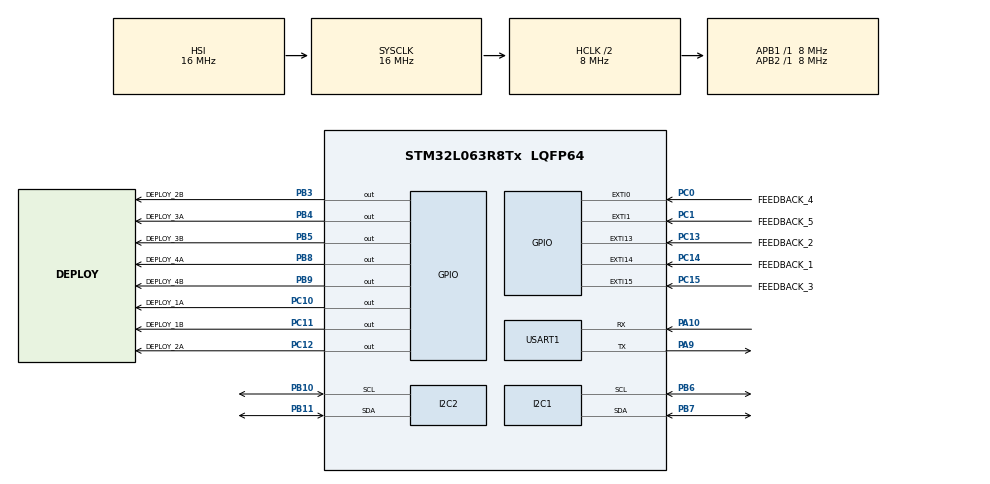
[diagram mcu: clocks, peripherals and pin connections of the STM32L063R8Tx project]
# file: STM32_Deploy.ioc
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ADC.ClockPrescaler=ADC_CLOCK_ASYNC_DIV64
ADC.ContinuousConvMode=DISABLE
ADC.DMAContinuousRequests=DISABLE
ADC.DataAlign=ADC_DATAALIGN_RIGHT
ADC.DiscontinuousConvMode=DISABLE
ADC.EOCSelection=ADC_EOC_SINGLE_CONV
ADC.EnableAnalogWatchDog=false
ADC.ExternalTrigConv=ADC_SOFTWARE_START
ADC.ExternalTrigConvEdge=ADC_EXTERNALTRIGCONVEDGE_NONE
ADC.LowPowerAutoPowerOff=DISABLE
ADC.LowPowerAutoWait=DISABLE
ADC.LowPowerFrequencyMode=DISABLE
ADC.Overrun=ADC_OVR_DATA_PRESERVED
ADC.OversamplingMode=DISABLE
ADC.Resolution=ADC_RESOLUTION_12B
ADC.SamplingTime=ADC_SAMPLETIME_12CYCLES_5
ADC.ScanConvMode=ADC_SCAN_DIRECTION_FORWARD
Dma.ADC.4.Direction=DMA_PERIPH_TO_MEMORY
Dma.ADC.4.Instance=DMA1_Channel1
Dma.ADC.4.MemDataAlignment=DMA_MDATAALIGN_HALFWORD
Dma.ADC.4.MemInc=DMA_MINC_ENABLE
Dma.ADC.4.Mode=DMA_NORMAL
Dma.ADC.4.PeriphDataAlignment=DMA_PDATAALIGN_HALFWORD
Dma.ADC.4.PeriphInc=DMA_PINC_DISABLE
Dma.ADC.4.Priority=DMA_PRIORITY_LOW
Dma.I2C1_RX.5.Direction=DMA_PERIPH_TO_MEMORY
Dma.I2C1_RX.5.Instance=DMA1_Channel7
Dma.I2C1_RX.5.MemDataAlignment=DMA_MDATAALIGN_BYTE
Dma.I2C1_RX.5.MemInc=DMA_MINC_ENABLE
Dma.I2C1_RX.5.Mode=DMA_NORMAL
Dma.I2C1_RX.5.PeriphDataAlignment=DMA_PDATAALIGN_BYTE
Dma.I2C1_RX.5.PeriphInc=DMA_PINC_DISABLE
Dma.I2C1_RX.5.Priority=DMA_PRIORITY_LOW
Dma.I2C1_TX.6.Direction=DMA_MEMORY_TO_PERIPH
Dma.I2C1_TX.6.Instance=DMA1_Channel6
Dma.I2C1_TX.6.MemDataAlignment=DMA_MDATAALIGN_BYTE
Dma.I2C1_TX.6.MemInc=DMA_MINC_ENABLE
Dma.I2C1_TX.6.Mode=DMA_NORMAL
Dma.I2C1_TX.6.PeriphDataAlignment=DMA_PDATAALIGN_BYTE
Dma.I2C1_TX.6.PeriphInc=DMA_PINC_DISABLE
Dma.I2C1_TX.6.Priority=DMA_PRIORITY_LOW
Dma.I2C2_RX.2.Direction=DMA_PERIPH_TO_MEMORY
Dma.I2C2_RX.2.Instance=DMA1_Channel5
Dma.I2C2_RX.2.MemDataAlignment=DMA_MDATAALIGN_BYTE
Dma.I2C2_RX.2.MemInc=DMA_MINC_ENABLE
Dma.I2C2_RX.2.Mode=DMA_NORMAL
Dma.I2C2_RX.2.PeriphDataAlignment=DMA_PDATAALIGN_BYTE
Dma.I2C2_RX.2.PeriphInc=DMA_PINC_DISABLE
Dma.I2C2_RX.2.Priority=DMA_PRIORITY_LOW
Dma.I2C2_TX.3.Direction=DMA_MEMORY_TO_PERIPH
Dma.I2C2_TX.3.Instance=DMA1_Channel4
Dma.I2C2_TX.3.MemDataAlignment=DMA_MDATAALIGN_BYTE
Dma.I2C2_TX.3.MemInc=DMA_MINC_ENABLE
Dma.I2C2_TX.3.Mode=DMA_NORMAL
Dma.I2C2_TX.3.PeriphDataAlignment=DMA_PDATAALIGN_BYTE
Dma.I2C2_TX.3.PeriphInc=DMA_PINC_DISABLE
Dma.I2C2_TX.3.Priority=DMA_PRIORITY_LOW
Dma.Request0=USART1_RX
Dma.Request1=USART1_TX
Dma.Request2=I2C2_RX
Dma.Request3=I2C2_TX
Dma.Request4=ADC
Dma.Request5=I2C1_RX
Dma.Request6=I2C1_TX
Dma.USART1_RX.0.Direction=DMA_PERIPH_TO_MEMORY
Dma.USART1_RX.0.Instance=DMA1_Channel3
Dma.USART1_RX.0.MemDataAlignment=DMA_MDATAALIGN_BYTE
Dma.USART1_RX.0.MemInc=DMA_MINC_ENABLE
Dma.USART1_RX.0.Mode=DMA_CIRCULAR
Dma.USART1_RX.0.PeriphDataAlignment=DMA_PDATAALIGN_BYTE
Dma.USART1_RX.0.PeriphInc=DMA_PINC_DISABLE
Dma.USART1_RX.0.Priority=DMA_PRIORITY_LOW
Dma.USART1_TX.1.Direction=DMA_MEMORY_TO_PERIPH
Dma.USART1_TX.1.Instance=DMA1_Channel2
Dma.USART1_TX.1.MemDataAlignment=DMA_MDATAALIGN_BYTE
Dma.USART1_TX.1.MemInc=DMA_MINC_ENABLE
Dma.USART1_TX.1.Mode=DMA_NORMAL
Dma.USART1_TX.1.PeriphDataAlignment=DMA_PDATAALIGN_BYTE
Dma.USART1_TX.1.PeriphInc=DMA_PINC_DISABLE
Dma.USART1_TX.1.Priority=DMA_PRIORITY_LOW
FREERTOS.MEMORY_ALLOCATION=1
FREERTOS.Tasks01=i2cTask,2,128,i2cWork,Default,NULL,Static,i2cTaskBuffer,i2cControlBlock;controlTask,0,64,controlWork,Default,NULL,Static,controlTaskBuffer,controlControlBlock
FREERTOS.configMINIMAL_STACK_SIZE=64
FREERTOS.configUSE_TICKLESS_IDLE=1
I2C1.OwnAddress=16
I2C1.Timing=0x2000090E
I2C2.Timing=0x2000090E
Mcu.Family=STM32L0
Mcu.Name=STM32L063R8Tx
Mcu.Package=LQFP64
NVIC.DMA1_Channel1_IRQn=true\:3\:0\:false\:false\:true\:true
NVIC.DMA1_Channel2_3_IRQn=true\:3\:0\:false\:false\:true\:true
NVIC.DMA1_Channel4_5_6_7_IRQn=true\:3\:0\:false\:false\:true\:true
NVIC.EXTI0_1_IRQn=true\:3\:0\:false\:false\:true\:true
NVIC.EXTI4_15_IRQn=true\:3\:0\:false\:false\:true\:true
NVIC.I2C1_IRQn=true\:3\:0\:false\:false\:true\:true
NVIC.I2C2_IRQn=true\:3\:0\:false\:false\:true\:true
NVIC.TIM2_IRQn=true\:3\:0\:false\:false\:true\:true
NVIC.TIM6_DAC_IRQn=true\:0\:0\:false\:false\:true\:false
NVIC.TimeBase=TIM6_DAC_IRQn
NVIC.TimeBaseIP=TIM6
PA10.Mode=Asynchronous
PA10.Signal=USART1_RX
PA9.Mode=Asynchronous
PA9.Signal=USART1_TX
PB10.Mode=I2C
PB10.Signal=I2C2_SCL
PB11.Mode=I2C
PB11.Signal=I2C2_SDA
PB3.GPIO_Label=DEPLOY_2B
PB3.Signal=GPIO_Output
PB4.GPIO_Label=DEPLOY_3A
PB4.Signal=GPIO_Output
PB5.GPIO_Label=DEPLOY_3B
PB5.Signal=GPIO_Output
PB6.Mode=I2C
PB6.Signal=I2C1_SCL
PB7.Mode=I2C
PB7.Signal=I2C1_SDA
PB8.GPIO_Label=DEPLOY_4A
PB8.Signal=GPIO_Output
PB9.GPIO_Label=DEPLOY_4B
PB9.Signal=GPIO_Output
PC0.GPIO_Label=FEEDBACK_4
PC0.GPIO_ModeDefaultEXTI=GPIO_MODE_IT_RISING
PC0.Signal=GPXTI0
PC1.GPIO_Label=FEEDBACK_5
PC1.Signal=GPXTI1
PC10.GPIO_Label=DEPLOY_1A
PC10.Signal=GPIO_Output
PC11.GPIO_Label=DEPLOY_1B
PC11.Signal=GPIO_Output
PC12.GPIO_Label=DEPLOY_2A
PC12.Signal=GPIO_Output
PC13.GPIO_Label=FEEDBACK_2
PC13.Signal=GPXTI13
PC14-OSC32_IN.GPIO_Label=FEEDBACK_1
PC14-OSC32_IN.Signal=GPXTI14
PC15-OSC32_OUT.GPIO_Label=FEEDBACK_3
PC15-OSC32_OUT.Signal=GPXTI15
ProjectManager.HeapSize=0x200
ProjectManager.StackSize=0x400
ProjectManager.TargetToolchain=SW4STM32
RCC.AHBCLKDivider=RCC_SYSCLK_DIV2
RCC.AHBFreq_Value=8000000
RCC.APB1Freq_Value=8000000
RCC.APB1TimFreq_Value=8000000
RCC.APB2Freq_Value=8000000
RCC.APB2TimFreq_Value=8000000
RCC.HCLKFreq_Value=8000000
RCC.HSE_VALUE=8000000
RCC.HSI16_VALUE=16000000
RCC.HSI48_VALUE=48000000
RCC.HSI_VALUE=16000000
RCC.LSE_VALUE=32768
RCC.MSI_VALUE=2097000
RCC.SYSCLKFreq_VALUE=16000000
RCC.SYSCLKSource=RCC_SYSCLKSOURCE_HSI
RCC.VCOOutputFreq_Value=48000000
TIM2.Period=1000
TIM2.Prescaler=8000
TIM2.TIM_MasterOutputTrigger=TIM_TRGO_RESET
USART1.OverSampling=UART_OVERSAMPLING_16
USART1.VirtualMode-Asynchronous=VM_ASYNC
USART1.WordLength=WORDLENGTH_8B
VP_ADC_TempSens_Input.Mode=IN-TempSens
VP_ADC_Vref_Input.Mode=IN-Vrefint
VP_FREERTOS_VS_ENABLE.Mode=Enabled
VP_SYS_VS_tim6.Mode=TIM6
VP_TIM2_VS_ClockSourceINT.Mode=Internal
VP_TIM2_VS_ClockSourceITR.Mode=TriggerSource_ITR0
VP_TIM2_VS_ControllerModeReset.Mode=Reset Mode
board=STM32_Deploy

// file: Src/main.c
/**
  ******************************************************************************
  * File Name          : main.c
  * Description        : Main program body
  ******************************************************************************
  * This notice applies to any and all portions of this file
  * that are not between comment pairs USER CODE BEGIN and
  * USER CODE END. Other portions of this file, whether
  * inserted by the user or by software development tools
  * are owned by their respective copyright owners.
  *
  * Copyright (c) 2017 STMicroelectronics International N.V.
  * All rights reserved.
  *
  * Redistribution and use in source and binary forms, with or without
  * modification, are permitted, provided that the following conditions are met:
  *
  * 1. Redistribution of source code must retain the above copyright notice,
  *    this list of conditions and the following disclaimer.
  * 2. Redistributions in binary form must reproduce the above copyright notice,
  *    this list of conditions and the following disclaimer in the documentation
  *    and/or other materials provided with the distribution.
  * 3. Neither the name of STMicroelectronics nor the names of other
  *    contributors to this software may be used to endorse or promote products
  *    derived from this software without specific written permission.
  * 4. This software, including modifications and/or derivative works of this
  *    software, must execute solely and exclusively on microcontroller or
  *    microprocessor devices manufactured by or for STMicroelectronics.
  * 5. Redistribution and use of this software other than as permitted under
  *    this license is void and will automatically terminate your rights under
  *    this license.
  *
  * THIS SOFTWARE IS PROVIDED BY STMICROELECTRONICS AND CONTRIBUTORS "AS IS"
  * AND ANY EXPRESS, IMPLIED OR STATUTORY WARRANTIES, INCLUDING, BUT NOT
  * LIMITED TO, THE IMPLIED WARRANTIES OF MERCHANTABILITY, FITNESS FOR A
  * PARTICULAR PURPOSE AND NON-INFRINGEMENT OF THIRD PARTY INTELLECTUAL PROPERTY
  * RIGHTS ARE DISCLAIMED TO THE FULLEST EXTENT PERMITTED BY LAW. IN NO EVENT
  * SHALL STMICROELECTRONICS OR CONTRIBUTORS BE LIABLE FOR ANY DIRECT, INDIRECT,
  * INCIDENTAL, SPECIAL, EXEMPLARY, OR CONSEQUENTIAL DAMAGES (INCLUDING, BUT NOT
  * LIMITED TO, PROCUREMENT OF SUBSTITUTE GOODS OR SERVICES; LOSS OF USE, DATA,
  * OR PROFITS; OR BUSINESS INTERRUPTION) HOWEVER CAUSED AND ON ANY THEORY OF
  * LIABILITY, WHETHER IN CONTRACT, STRICT LIABILITY, OR TORT (INCLUDING
  * NEGLIGENCE OR OTHERWISE) ARISING IN ANY WAY OUT OF THE USE OF THIS SOFTWARE,
  * EVEN IF ADVISED OF THE POSSIBILITY OF SUCH DAMAGE.
  *
  ******************************************************************************
  */
#include "main.h"
#include "stm32l0xx_hal.h"
#include "cmsis_os.h"

/* USER CODE BEGIN Includes */
#include <string.h>
#include "utils.h"
#include "deploy_execution.h"
/* USER CODE END Includes */

ADC_HandleTypeDef hadc;
DMA_HandleTypeDef hdma_adc;

I2C_HandleTypeDef hi2c1;
I2C_HandleTypeDef hi2c2;
DMA_HandleTypeDef hdma_i2c1_rx;
DMA_HandleTypeDef hdma_i2c1_tx;
DMA_HandleTypeDef hdma_i2c2_rx;
DMA_HandleTypeDef hdma_i2c2_tx;

TIM_HandleTypeDef htim2;

UART_HandleTypeDef huart1;
DMA_HandleTypeDef hdma_usart1_rx;
DMA_HandleTypeDef hdma_usart1_tx;

osThreadId i2cTaskHandle;
uint32_t i2cTaskBuffer[ 128 ];
osStaticThreadDef_t i2cControlBlock;
osThreadId controlTaskHandle;
uint32_t controlTaskBuffer[ 64 ];
osStaticThreadDef_t controlControlBlock;

/* USER CODE BEGIN PV */
/* Private variables ---------------------------------------------------------*/

/* USER CODE END PV */

void SystemClock_Config(void);
static void MX_GPIO_Init(void);
static void MX_DMA_Init(void);
static void MX_I2C2_Init(void);
static void MX_I2C1_Init(void);
static void MX_USART1_UART_Init(void);
static void MX_TIM2_Init(void);
static void MX_ADC_Init(void);
void i2cWork(void const * argument);
void controlWork(void const * argument);

/* USER CODE BEGIN PFP */
/* Private function prototypes -----------------------------------------------*/

/* USER CODE END PFP */

int main(void)
{

  /* MCU Configuration----------------------------------------------------------*/

  /* Reset of all peripherals, Initializes the Flash interface and the Systick. */
  HAL_Init();

  /* Configure the system clock */
  SystemClock_Config();

  /* Initialize all configured peripherals */
  MX_GPIO_Init();
  MX_DMA_Init();
  MX_I2C2_Init();
  MX_I2C1_Init();
  MX_USART1_UART_Init();
  MX_TIM2_Init();
  MX_ADC_Init();

  /* USER CODE BEGIN 2 */
  initialize_temp_sensor();

  /* USER CODE END 2 */

  /* Create the thread(s) */
  /* definition and creation of i2cTask */
  osThreadStaticDef(i2cTask, i2cWork, osPriorityHigh, 0, 128, i2cTaskBuffer, &i2cControlBlock);
  i2cTaskHandle = osThreadCreate(osThread(i2cTask), NULL);

  /* definition and creation of controlTask */
  osThreadStaticDef(controlTask, controlWork, osPriorityNormal, 0, 64, controlTaskBuffer, &controlControlBlock);
  controlTaskHandle = osThreadCreate(osThread(controlTask), NULL);

  /* Start scheduler */
  osKernelStart();

  /* We should never get here as control is now taken by the scheduler */

  /* Infinite loop */
  while (1)
  {

  }

}

/** System Clock Configuration
*/
void SystemClock_Config(void)
{

  RCC_OscInitTypeDef RCC_OscInitStruct;
  RCC_ClkInitTypeDef RCC_ClkInitStruct;
  RCC_PeriphCLKInitTypeDef PeriphClkInit;

    /**Configure the main internal regulator output voltage
    */
  __HAL_PWR_VOLTAGESCALING_CONFIG(PWR_REGULATOR_VOLTAGE_SCALE1);

    /**Initializes the CPU, AHB and APB busses clocks
    */
  RCC_OscInitStruct.OscillatorType = RCC_OSCILLATORTYPE_HSI;
  RCC_OscInitStruct.HSIState = RCC_HSI_ON;
  RCC_OscInitStruct.HSICalibrationValue = 16;
  RCC_OscInitStruct.PLL.PLLState = RCC_PLL_NONE;
  if (HAL_RCC_OscConfig(&RCC_OscInitStruct) != HAL_OK)
  {
    _Error_Handler(__FILE__, __LINE__);
  }

    /**Initializes the CPU, AHB and APB busses clocks
    */
  RCC_ClkInitStruct.ClockType = RCC_CLOCKTYPE_HCLK|RCC_CLOCKTYPE_SYSCLK
                              |RCC_CLOCKTYPE_PCLK1|RCC_CLOCKTYPE_PCLK2;
  RCC_ClkInitStruct.SYSCLKSource = RCC_SYSCLKSOURCE_HSI;
  RCC_ClkInitStruct.AHBCLKDivider = RCC_SYSCLK_DIV2;
  RCC_ClkInitStruct.APB1CLKDivider = RCC_HCLK_DIV1;
  RCC_ClkInitStruct.APB2CLKDivider = RCC_HCLK_DIV1;

  if (HAL_RCC_ClockConfig(&RCC_ClkInitStruct, FLASH_LATENCY_0) != HAL_OK)
  {
    _Error_Handler(__FILE__, __LINE__);
  }

  PeriphClkInit.PeriphClockSelection = RCC_PERIPHCLK_USART1|RCC_PERIPHCLK_I2C1;
  PeriphClkInit.Usart1ClockSelection = RCC_USART1CLKSOURCE_PCLK2;
  PeriphClkInit.I2c1ClockSelection = RCC_I2C1CLKSOURCE_PCLK1;
  if (HAL_RCCEx_PeriphCLKConfig(&PeriphClkInit) != HAL_OK)
  {
    _Error_Handler(__FILE__, __LINE__);
  }

    /**Configure the Systick interrupt time
    */
  HAL_SYSTICK_Config(HAL_RCC_GetHCLKFreq()/1000);

    /**Configure the Systick
    */
  HAL_SYSTICK_CLKSourceConfig(SYSTICK_CLKSOURCE_HCLK);

  /* SysTick_IRQn interrupt configuration */
  HAL_NVIC_SetPriority(SysTick_IRQn, 3, 0);
}

/* ADC init function */
static void MX_ADC_Init(void)
{

  ADC_ChannelConfTypeDef sConfig;

    /**Configure the global features of the ADC (Clock, Resolution, Data Alignment and number of conversion)
    */
  hadc.Instance = ADC1;
  hadc.Init.OversamplingMode = DISABLE;
  hadc.Init.ClockPrescaler = ADC_CLOCK_ASYNC_DIV64;
  hadc.Init.Resolution = ADC_RESOLUTION_12B;
  hadc.Init.SamplingTime = ADC_SAMPLETIME_12CYCLES_5;
  hadc.Init.ScanConvMode = ADC_SCAN_DIRECTION_FORWARD;
  hadc.Init.DataAlign = ADC_DATAALIGN_RIGHT;
  hadc.Init.ContinuousConvMode = DISABLE;
  hadc.Init.DiscontinuousConvMode = DISABLE;
  hadc.Init.ExternalTrigConvEdge = ADC_EXTERNALTRIGCONVEDGE_NONE;
  hadc.Init.ExternalTrigConv = ADC_SOFTWARE_START;
  hadc.Init.DMAContinuousRequests = DISABLE;
  hadc.Init.EOCSelection = ADC_EOC_SINGLE_CONV;
  hadc.Init.Overrun = ADC_OVR_DATA_PRESERVED;
  hadc.Init.LowPowerAutoWait = DISABLE;
  hadc.Init.LowPowerFrequencyMode = DISABLE;
  hadc.Init.LowPowerAutoPowerOff = DISABLE;
  if (HAL_ADC_Init(&hadc) != HAL_OK)
  {
    _Error_Handler(__FILE__, __LINE__);
  }

    /**Configure for the selected ADC regular channel to be converted.
    */
  sConfig.Channel = ADC_CHANNEL_TEMPSENSOR;
  sConfig.Rank = ADC_RANK_CHANNEL_NUMBER;
  if (HAL_ADC_ConfigChannel(&hadc, &sConfig) != HAL_OK)
  {
    _Error_Handler(__FILE__, __LINE__);
  }

    /**Configure for the selected ADC regular channel to be converted.
    */
  sConfig.Channel = ADC_CHANNEL_VREFINT;
  if (HAL_ADC_ConfigChannel(&hadc, &sConfig) != HAL_OK)
  {
    _Error_Handler(__FILE__, __LINE__);
  }

}

/* I2C1 init function */
static void MX_I2C1_Init(void)
{

  hi2c1.Instance = I2C1;
  hi2c1.Init.Timing = 0x2000090E;
  hi2c1.Init.OwnAddress1 = 32;
  hi2c1.Init.AddressingMode = I2C_ADDRESSINGMODE_7BIT;
  hi2c1.Init.DualAddressMode = I2C_DUALADDRESS_DISABLE;
  hi2c1.Init.OwnAddress2 = 0;
  hi2c1.Init.OwnAddress2Masks = I2C_OA2_NOMASK;
  hi2c1.Init.GeneralCallMode = I2C_GENERALCALL_DISABLE;
  hi2c1.Init.NoStretchMode = I2C_NOSTRETCH_DISABLE;
  if (HAL_I2C_Init(&hi2c1) != HAL_OK)
  {
    _Error_Handler(__FILE__, __LINE__);
  }

    /**Configure Analogue filter
    */
  if (HAL_I2CEx_ConfigAnalogFilter(&hi2c1, I2C_ANALOGFILTER_ENABLE) != HAL_OK)
  {
    _Error_Handler(__FILE__, __LINE__);
  }

    /**Configure Digital filter
    */
  if (HAL_I2CEx_ConfigDigitalFilter(&hi2c1, 0) != HAL_OK)
  {
    _Error_Handler(__FILE__, __LINE__);
  }

}

/* I2C2 init function */
static void MX_I2C2_Init(void)
{

  hi2c2.Instance = I2C2;
  hi2c2.Init.Timing = 0x2000090E;
  hi2c2.Init.OwnAddress1 = 0;
  hi2c2.Init.AddressingMode = I2C_ADDRESSINGMODE_7BIT;
  hi2c2.Init.DualAddressMode = I2C_DUALADDRESS_DISABLE;
  hi2c2.Init.OwnAddress2 = 0;
  hi2c2.Init.OwnAddress2Masks = I2C_OA2_NOMASK;
  hi2c2.Init.GeneralCallMode = I2C_GENERALCALL_DISABLE;
  hi2c2.Init.NoStretchMode = I2C_NOSTRETCH_DISABLE;
  if (HAL_I2C_Init(&hi2c2) != HAL_OK)
  {
    _Error_Handler(__FILE__, __LINE__);
  }

    /**Configure Analogue filter
    */
  if (HAL_I2CEx_ConfigAnalogFilter(&hi2c2, I2C_ANALOGFILTER_ENABLE) != HAL_OK)
  {
    _Error_Handler(__FILE__, __LINE__);
  }

    /**Configure Digital filter
    */
  if (HAL_I2CEx_ConfigDigitalFilter(&hi2c2, 0) != HAL_OK)
  {
    _Error_Handler(__FILE__, __LINE__);
  }

}

/* TIM2 init function */
static void MX_TIM2_Init(void)
{

  TIM_ClockConfigTypeDef sClockSourceConfig;
  TIM_SlaveConfigTypeDef sSlaveConfig;
  TIM_MasterConfigTypeDef sMasterConfig;

  htim2.Instance = TIM2;
  htim2.Init.Prescaler = 8000;
  htim2.Init.CounterMode = TIM_COUNTERMODE_UP;
  htim2.Init.Period = 1000;
  htim2.Init.ClockDivision = TIM_CLOCKDIVISION_DIV1;
  if (HAL_TIM_Base_Init(&htim2) != HAL_OK)
  {
    _Error_Handler(__FILE__, __LINE__);
  }

  sClockSourceConfig.ClockSource = TIM_CLOCKSOURCE_INTERNAL;
  if (HAL_TIM_ConfigClockSource(&htim2, &sClockSourceConfig) != HAL_OK)
  {
    _Error_Handler(__FILE__, __LINE__);
  }

  sSlaveConfig.SlaveMode = TIM_SLAVEMODE_RESET;
  sSlaveConfig.InputTrigger = TIM_TS_ITR0;
  if (HAL_TIM_SlaveConfigSynchronization(&htim2, &sSlaveConfig) != HAL_OK)
  {
    _Error_Handler(__FILE__, __LINE__);
  }

  sMasterConfig.MasterOutputTrigger = TIM_TRGO_RESET;
  sMasterConfig.MasterSlaveMode = TIM_MASTERSLAVEMODE_DISABLE;
  if (HAL_TIMEx_MasterConfigSynchronization(&htim2, &sMasterConfig) != HAL_OK)
  {
    _Error_Handler(__FILE__, __LINE__);
  }

}

/* USART1 init function */
static void MX_USART1_UART_Init(void)
{

  huart1.Instance = USART1;
  huart1.Init.BaudRate = 115200;
  huart1.Init.WordLength = UART_WORDLENGTH_8B;
  huart1.Init.StopBits = UART_STOPBITS_1;
  huart1.Init.Parity = UART_PARITY_NONE;
  huart1.Init.Mode = UART_MODE_TX_RX;
  huart1.Init.HwFlowCtl = UART_HWCONTROL_NONE;
  huart1.Init.OverSampling = UART_OVERSAMPLING_16;
  huart1.Init.OneBitSampling = UART_ONE_BIT_SAMPLE_DISABLE;
  huart1.AdvancedInit.AdvFeatureInit = UART_ADVFEATURE_NO_INIT;
  if (HAL_UART_Init(&huart1) != HAL_OK)
  {
    _Error_Handler(__FILE__, __LINE__);
  }

}

static void MX_DMA_Init(void)
{
  /* DMA controller clock enable */
  __HAL_RCC_DMA1_CLK_ENABLE();

  /* DMA interrupt init */
  /* DMA1_Channel1_IRQn interrupt configuration */
  HAL_NVIC_SetPriority(DMA1_Channel1_IRQn, 3, 0);
  HAL_NVIC_EnableIRQ(DMA1_Channel1_IRQn);
  /* DMA1_Channel2_3_IRQn interrupt configuration */
  HAL_NVIC_SetPriority(DMA1_Channel2_3_IRQn, 3, 0);
  HAL_NVIC_EnableIRQ(DMA1_Channel2_3_IRQn);
  /* DMA1_Channel4_5_6_7_IRQn interrupt configuration */
  HAL_NVIC_SetPriority(DMA1_Channel4_5_6_7_IRQn, 3, 0);
  HAL_NVIC_EnableIRQ(DMA1_Channel4_5_6_7_IRQn);

}

/** Configure pins as
        * Analog
        * Input
        * Output
        * EVENT_OUT
        * EXTI
*/
static void MX_GPIO_Init(void)
{

  GPIO_InitTypeDef GPIO_InitStruct;

  /* GPIO Ports Clock Enable */
  __HAL_RCC_GPIOC_CLK_ENABLE();
  __HAL_RCC_GPIOB_CLK_ENABLE();
  __HAL_RCC_GPIOA_CLK_ENABLE();

  /*Configure GPIO pin Output Level */
  HAL_GPIO_WritePin(GPIOC, DEPLOY_1A_Pin|DEPLOY_1B_Pin|DEPLOY_2A_Pin, GPIO_PIN_RESET);

  /*Configure GPIO pin Output Level */
  HAL_GPIO_WritePin(GPIOB, DEPLOY_2B_Pin|DEPLOY_3A_Pin|DEPLOY_3B_Pin|DEPLOY_4A_Pin
                          |DEPLOY_4B_Pin, GPIO_PIN_RESET);

  /*Configure GPIO pins : FEEDBACK_2_Pin FEEDBACK_1_Pin FEEDBACK_3_Pin FEEDBACK_4_Pin
                           FEEDBACK_5_Pin */
  GPIO_InitStruct.Pin = FEEDBACK_2_Pin|FEEDBACK_1_Pin|FEEDBACK_3_Pin|FEEDBACK_4_Pin
                          |FEEDBACK_5_Pin;
  GPIO_InitStruct.Mode = GPIO_MODE_IT_RISING;
  GPIO_InitStruct.Pull = GPIO_NOPULL;
  HAL_GPIO_Init(GPIOC, &GPIO_InitStruct);

  /*Configure GPIO pins : DEPLOY_1A_Pin DEPLOY_1B_Pin DEPLOY_2A_Pin */
  GPIO_InitStruct.Pin = DEPLOY_1A_Pin|DEPLOY_1B_Pin|DEPLOY_2A_Pin;
  GPIO_InitStruct.Mode = GPIO_MODE_OUTPUT_PP;
  GPIO_InitStruct.Pull = GPIO_NOPULL;
  GPIO_InitStruct.Speed = GPIO_SPEED_FREQ_LOW;
  HAL_GPIO_Init(GPIOC, &GPIO_InitStruct);

  /*Configure GPIO pins : DEPLOY_2B_Pin DEPLOY_3A_Pin DEPLOY_3B_Pin DEPLOY_4A_Pin
                           DEPLOY_4B_Pin */
  GPIO_InitStruct.Pin = DEPLOY_2B_Pin|DEPLOY_3A_Pin|DEPLOY_3B_Pin|DEPLOY_4A_Pin
                          |DEPLOY_4B_Pin;
  GPIO_InitStruct.Mode = GPIO_MODE_OUTPUT_PP;
  GPIO_InitStruct.Pull = GPIO_NOPULL;
  GPIO_InitStruct.Speed = GPIO_SPEED_FREQ_LOW;
  HAL_GPIO_Init(GPIOB, &GPIO_InitStruct);

  /* EXTI interrupt init*/
  HAL_NVIC_SetPriority(EXTI0_1_IRQn, 3, 0);
  //HAL_NVIC_EnableIRQ(EXTI0_1_IRQn);

  HAL_NVIC_SetPriority(EXTI4_15_IRQn, 3, 0);
  //HAL_NVIC_EnableIRQ(EXTI4_15_IRQn);

}

/* i2cWork function */
void i2cWork(void const * argument)
{

  /* USER CODE BEGIN 5 */
	deploy_command_t cmd;
  /* Infinite loop */
  for(;;)
  {
	  turn_i2c_rx();
	  if (i2c_slave_message()) {
		  get_i2c_message(&cmd);
		  process_incoming(&cmd);
	  }
  }
  /* USER CODE END 5 */
}

/* controlWork function */
void controlWork(void const * argument)
{
  /* USER CODE BEGIN controlWork */
  /* Infinite loop */
  for(;;)
  {
	  deploy_work();
  }
  /* USER CODE END controlWork */
}

void HAL_TIM_PeriodElapsedCallback(TIM_HandleTypeDef *htim)
{
  if (htim->Instance == TIM6) {
    HAL_IncTick();
  }
}

void _Error_Handler(char * file, int line)
{
  while(1)
  {
  }
}

/************************ (C) COPYRIGHT STMicroelectronics *****END OF FILE****/

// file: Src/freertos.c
/**
  ******************************************************************************
  * File Name          : freertos.c
  * Description        : Code for freertos applications
  ******************************************************************************
  * This notice applies to any and all portions of this file
  * that are not between comment pairs USER CODE BEGIN and
  * USER CODE END. Other portions of this file, whether
  * inserted by the user or by software development tools
  * are owned by their respective copyright owners.
  *
  * Copyright (c) 2017 STMicroelectronics International N.V.
  * All rights reserved.
  *
  * Redistribution and use in source and binary forms, with or without
  * modification, are permitted, provided that the following conditions are met:
  *
  * 1. Redistribution of source code must retain the above copyright notice,
  *    this list of conditions and the following disclaimer.
  * 2. Redistributions in binary form must reproduce the above copyright notice,
  *    this list of conditions and the following disclaimer in the documentation
  *    and/or other materials provided with the distribution.
  * 3. Neither the name of STMicroelectronics nor the names of other
  *    contributors to this software may be used to endorse or promote products
  *    derived from this software without specific written permission.
  * 4. This software, including modifications and/or derivative works of this
  *    software, must execute solely and exclusively on microcontroller or
  *    microprocessor devices manufactured by or for STMicroelectronics.
  * 5. Redistribution and use of this software other than as permitted under
  *    this license is void and will automatically terminate your rights under
  *    this license.
  *
  * THIS SOFTWARE IS PROVIDED BY STMICROELECTRONICS AND CONTRIBUTORS "AS IS"
  * AND ANY EXPRESS, IMPLIED OR STATUTORY WARRANTIES, INCLUDING, BUT NOT
  * LIMITED TO, THE IMPLIED WARRANTIES OF MERCHANTABILITY, FITNESS FOR A
  * PARTICULAR PURPOSE AND NON-INFRINGEMENT OF THIRD PARTY INTELLECTUAL PROPERTY
  * RIGHTS ARE DISCLAIMED TO THE FULLEST EXTENT PERMITTED BY LAW. IN NO EVENT
  * SHALL STMICROELECTRONICS OR CONTRIBUTORS BE LIABLE FOR ANY DIRECT, INDIRECT,
  * INCIDENTAL, SPECIAL, EXEMPLARY, OR CONSEQUENTIAL DAMAGES (INCLUDING, BUT NOT
  * LIMITED TO, PROCUREMENT OF SUBSTITUTE GOODS OR SERVICES; LOSS OF USE, DATA,
  * OR PROFITS; OR BUSINESS INTERRUPTION) HOWEVER CAUSED AND ON ANY THEORY OF
  * LIABILITY, WHETHER IN CONTRACT, STRICT LIABILITY, OR TORT (INCLUDING
  * NEGLIGENCE OR OTHERWISE) ARISING IN ANY WAY OUT OF THE USE OF THIS SOFTWARE,
  * EVEN IF ADVISED OF THE POSSIBILITY OF SUCH DAMAGE.
  *
  ******************************************************************************
  */

#include "FreeRTOS.h"
#include "task.h"

/* Pre/Post sleep processing prototypes */
void PreSleepProcessing(uint32_t *ulExpectedIdleTime);
void PostSleepProcessing(uint32_t *ulExpectedIdleTime);

/* GetIdleTaskMemory prototype (linked to static allocation support) */
void vApplicationGetIdleTaskMemory( StaticTask_t **ppxIdleTaskTCBBuffer, StackType_t **ppxIdleTaskStackBuffer, uint32_t *pulIdleTaskStackSize );

/* Hook prototypes */

/* USER CODE BEGIN PREPOSTSLEEP */
__weak void PreSleepProcessing(uint32_t *ulExpectedIdleTime)
{
/* place for user code */
}

__weak void PostSleepProcessing(uint32_t *ulExpectedIdleTime)
{
/* place for user code */
}
/* USER CODE END PREPOSTSLEEP */

/* USER CODE BEGIN GET_IDLE_TASK_MEMORY */
static StaticTask_t xIdleTaskTCBBuffer;
static StackType_t xIdleStack[configMINIMAL_STACK_SIZE];

void vApplicationGetIdleTaskMemory( StaticTask_t **ppxIdleTaskTCBBuffer, StackType_t **ppxIdleTaskStackBuffer, uint32_t *pulIdleTaskStackSize )
{
  *ppxIdleTaskTCBBuffer = &xIdleTaskTCBBuffer;
  *ppxIdleTaskStackBuffer = &xIdleStack[0];
  *pulIdleTaskStackSize = configMINIMAL_STACK_SIZE;
  /* place for user code */
}
/* USER CODE END GET_IDLE_TASK_MEMORY */

/************************ (C) COPYRIGHT STMicroelectronics *****END OF FILE****/
